# DSP_PRM register map
Vendor: Texas Instruments
Peripheral module from a debugger description file (folder omap5430_ES2_PUBLIC).
Registers are 32-bit, access not given, reset 0x3F0707 unless marked. A register's access mark holds for its fields unless they carry their own. Offsets are as the file gives them; lines under a group give offsets from that group; [hi:lo] are bit positions; {n}, {i} and the like mark numbered series; 'fields as' and 'values as' point back to an identical list; <NAME> marks a mode.

## DSP_PRM
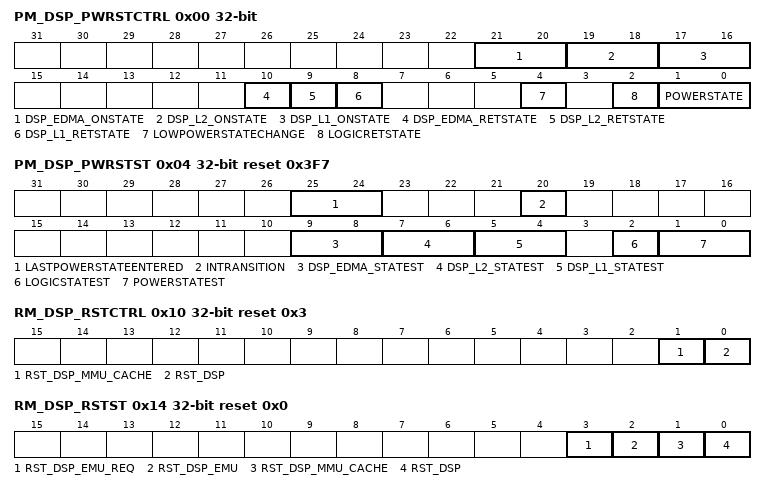
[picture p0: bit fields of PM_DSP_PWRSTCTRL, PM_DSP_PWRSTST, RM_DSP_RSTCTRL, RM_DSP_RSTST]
0x00 PM_DSP_PWRSTCTRL — This register controls the DSP power state to reach upon a domain sleep transition
  [21:20] DSP_EDMA_ONSTATE ro — DSP_EDMA state when domain is ON.
    3=Mem_on (Memory bank is on when the domain is ON.)
  [19:18] DSP_L2_ONSTATE ro — DSP_L2 state when domain is ON.
    3=Mem_on (Memory bank is on when the domain is ON.)
  [17:16] DSP_L1_ONSTATE ro — DSP_L1 state when domain is ON.
    3=Mem_on (Memory bank is on when the domain is ON.)
  [10] DSP_EDMA_RETSTATE ro — DSP_EDMA state when domain is RETENTION.
    1=mem_ret (Memory bank is retained when domain is in RETENTION state.)
  [9] DSP_L2_RETSTATE rw — DSP_L2 state when domain is RETENTION.
    0=mem_off (Memory bank is off when the domain is in the RETENTION state.); 1=mem_ret (Memory bank is retained when domain is in RETENTION state.)
  [8] DSP_L1_RETSTATE rw — DSP_L2 state when domain is RETENTION.
    values as DSP_L2_RETSTATE
  [4] LOWPOWERSTATECHANGE — Power state change request when domain has already performed a sleep transition. Allows going into deeper low power state without waking up the power domain. (access RW WSpecial)
    0=DIS (Do not request a low power state change.); 1=EN (Request a low power state change. This bit is automatically cleared when the power state is effectively changed or when power state is ON.)
  [2] LOGICRETSTATE rw — Logic state when power domain is RETENTION
    0=logic_off (Only retention registers are retained and remaing logic is off when the domain is in RETENTION state.); 1=logic_ret (Whole logic is retained when domain is in RETENTION state.)
  [1:0] POWERSTATE rw — Power state control
    0=OFF (Reserved); 1=RET (RETENTION state); 2=INACT (INACTIVE state); 3=ON (ON State)
0x04 PM_DSP_PWRSTST reset 0x3F7 — This register provides a status on the DSP domain current power state. [warm reset insensitive]
  [25:24] LASTPOWERSTATEENTERED — Last low power state entered. Set to 0x3 upon write of the same only. This register is intended for debug purpose only. (access RW W1toSet)
    3=ON (Power domain was previously ON-ACTIVE); 2=INACTIVE (Power domain was previously ON-INACTIVE); 1=RET (Power domain was previously in RETENTION); 0=OFF (Reserved)
  [20] INTRANSITION ro — Domain transition status
    0=No (No on-going transition on power domain); 1=Ongoing (Power domain transition is in progress.)
  [9:8] DSP_EDMA_STATEST ro — DSP_EDMA memory state status
    0=Mem_off (Reserved); 1=Mem_ret (Memory is RETENTION); 3=Mem_on (Memory is ON)
  [7:6] DSP_L2_STATEST ro — DSP_L2 memory state status
    values as DSP_EDMA_STATEST
  [5:4] DSP_L1_STATEST ro — DSP_L1 memory state status
    values as DSP_EDMA_STATEST
  [2] LOGICSTATEST ro — Logic state status
    0=OFF (Logic in domain is OFF); 1=ON (Logic in domain is ON)
  [1:0] POWERSTATEST ro — Current power state status
    0=OFF (Reserved); 1=RET (Power domain is in RETENTION); 2=INACTIVE (Power domain is ON-INACTIVE); 3=ON (Power domain is ON-ACTIVE)
0x10 RM_DSP_RSTCTRL access per field reset 0x3 — This register controls the release of the DSP sub-system resets.
  [1] RST_DSP_MMU_CACHE rw — DSP MMU, cache and slave interface reset control
    0=CLEAR (Reset is cleared for the MMU, cache and slave interface); 1=ASSERT (Reset is asserted for the MMU, cache and slave interface)
  [0] RST_DSP rw — DSP reset control
    0=CLEAR (Reset is cleared for the DSP); 1=ASSERT (Reset is asserted for the DSP)
0x14 RM_DSP_RSTST reset 0x0 — This register logs the different reset sources of the DSP domain. Each bit is set upon release of the domain reset signal. Must be cleared by software. [warm reset insensitive]
  [3] RST_DSP_EMU_REQ — DSP processor has been reset due to DSP emulation reset request driven from DSP SS (access RW W1toClr)
    0=RESET_NO (No emulation reset); 1=RESET_YES (DSP has been reset upon emulation reset request)
  [2] RST_DSP_EMU — DSP domain has been reset due to emulation reset source e.g. assert reset command initiated by the icepick module (access RW W1toClr)
    0=RESET_NO (No emulation reset); 1=RESET_YES (DSP has been reset upon emulation reset)
  [1] RST_DSP_MMU_CACHE — DSP MMU, cache and slave interface SW reset status (access RW W1toClr)
    0=RESET_NO (No SW reset occured); 1=RESET_YES (MMU, cache and slave interface has been reset upon SW reset)
  [0] RST_DSP — DSP SW reset (access RW W1toClr)
    0=RESET_NO (No SW reset occured); 1=RESET_YES (DSP has been reset upon SW reset)
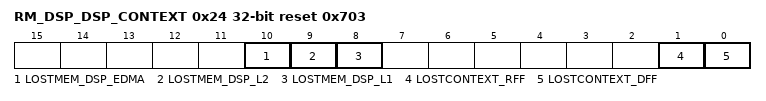
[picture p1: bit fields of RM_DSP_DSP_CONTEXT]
0x24 RM_DSP_DSP_CONTEXT reset 0x703 — This register contains dedicated DSP context statuses. [warm reset insensitive]
  [all] fields
    0=Maintained (Context has been maintained); 1=Lost (Context has been lost)
  [10] LOSTMEM_DSP_EDMA — Specify if memory-based context in DSP_EDMA memory bank has been lost due to a previous power transition or other reset source. (access RW W1toClr)
  [9] LOSTMEM_DSP_L2 — Specify if memory-based context in DSP_L2 memory bank has been lost due to a previous power transition or other reset source. (access RW W1toClr)
  [8] LOSTMEM_DSP_L1 — Specify if memory-based context in DSP_L1 memory bank has been lost due to a previous power transition or other reset source. (access RW W1toClr)
  [1] LOSTCONTEXT_RFF — Specify if RFF-based context has been lost due to a previous power transition or other reset source. (set upon assertion of DSP_RET_RST signal) (access RW W1toClr)
  [0] LOSTCONTEXT_DFF — Specify if DFF-based context has been lost due to a previous power transition or other reset source. (set upon assertion of DSP_SYS_RST signal) (access RW W1toClr)
